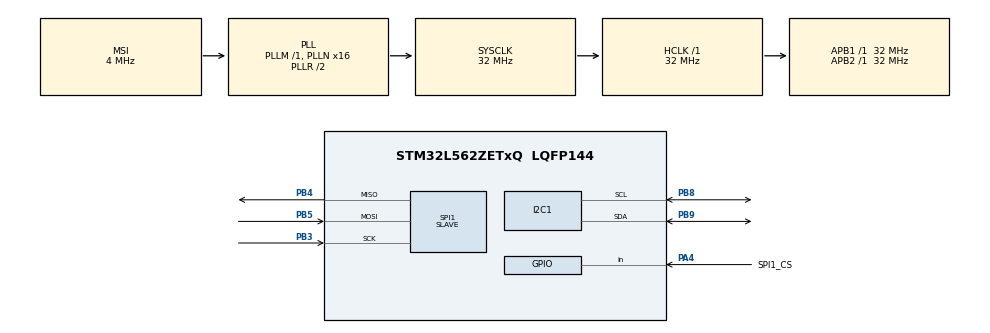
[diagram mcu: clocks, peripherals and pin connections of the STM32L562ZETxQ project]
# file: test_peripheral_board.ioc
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I2C1.OwnAddress=1
I2C1.Timing=0x00B07CB4
Mcu.Family=STM32L5
Mcu.Name=STM32L562ZETxQ
Mcu.Package=LQFP144
NVIC.PriorityGroup=NVIC_PRIORITYGROUP_3
PA4.GPIO_Label=SPI1_CS
PA4.Signal=GPIO_Input
PB3\ (JTDO/TRACESWO).Mode=Full_Duplex_Slave
PB3\ (JTDO/TRACESWO).Signal=SPI1_SCK
PB4\ (NJTRST).Mode=Full_Duplex_Slave
PB4\ (NJTRST).Signal=SPI1_MISO
PB5.Mode=Full_Duplex_Slave
PB5.Signal=SPI1_MOSI
PB8.Mode=I2C
PB8.Signal=I2C1_SCL
PB9.Mode=I2C
PB9.Signal=I2C1_SDA
ProjectManager.HeapSize=0x200
ProjectManager.StackSize=0x400
ProjectManager.TargetToolchain=STM32CubeIDE
RCC.AHBFreq_Value=32000000
RCC.APB1Freq_Value=32000000
RCC.APB1TimFreq_Value=32000000
RCC.APB2Freq_Value=32000000
RCC.APB2TimFreq_Value=32000000
RCC.CSICalibrationValue=32
RCC.CortexFreq_Value=32000000
RCC.HCLKFreq_Value=32000000
RCC.HSE_VALUE=16000000
RCC.HSI48_VALUE=48000000
RCC.HSI_VALUE=16000000
RCC.LSE_VALUE=32768
RCC.MSI_VALUE=4000000
RCC.PLL1_VCI_Range=RCC_PLL1VCIRANGE_3
RCC.PLL1_VCO_SEL=RCC_PLL1VCOMEDIUM
RCC.PLL2FRACN=0
RCC.PLL2_VCI_Range=RCC_PLL2VCIRANGE_3
RCC.PLL2_VCO_SEL=RCC_PLL2VCOWIDE
RCC.PLL3FRACN=0
RCC.PLL3_VCI_Range=RCC_PLL3VCIRANGE_3
RCC.PLL3_VCO_SEL=RCC_PLL3VCOWIDE
RCC.PLLFRACN=0
RCC.PLLN=16
RCC.ProductRev=revV
RCC.RCC_TIM_PRescaler_Selection=RCC_TIMPRES_DESACTIVATED
RCC.SYSCLKFreq_VALUE=32000000
RCC.SYSCLKSource=RCC_SYSCLKSOURCE_PLLCLK
RCC.VCOOutputFreq_Value=64000000
SPI1.DataSize=SPI_DATASIZE_8BIT
SPI1.Direction=SPI_DIRECTION_2LINES
SPI1.Mode=SPI_MODE_SLAVE
SPI1.VirtualType=VM_SLAVE
VP_PWR_VS_DBSignals.Mode=DisableDeadBatterySignals
VP_PWR_VS_SECSignals.Mode=Security/Privilege
board=custom

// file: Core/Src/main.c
/* USER CODE BEGIN Header */
/**
  ******************************************************************************
  * @file           : main.c
  * @brief          : Main program body
  ******************************************************************************
  * @attention
  *
  * Copyright (c) 2025 STMicroelectronics.
  * All rights reserved.
  *
  * This software is licensed under terms that can be found in the LICENSE file
  * in the root directory of this software component.
  * If no LICENSE file comes with this software, it is provided AS-IS.
  *
  ******************************************************************************
  */
/* USER CODE END Header */
#include "main.h"

I2C_HandleTypeDef hi2c1;

SPI_HandleTypeDef hspi1;

void SystemClock_Config(void);
static void MX_GPIO_Init(void);
static void MX_SPI1_Init(void);
static void MX_I2C1_Init(void);

int main(void)
{

  /* MCU Configuration--------------------------------------------------------*/

  /* Reset of all peripherals, Initializes the Flash interface and the Systick. */
  HAL_Init();

  /* Configure the system clock */
  SystemClock_Config();

  /* Initialize all configured peripherals */
  MX_GPIO_Init();
  MX_SPI1_Init();
  MX_I2C1_Init();

  /* Infinite loop */
  /* USER CODE BEGIN WHILE */
  while (1)
  {
	  //HAL_SPI_TransmitReceive(&hspi1, txData, rxData, 3, HAL_MAX_DELAY);
	  //HAL_I2C_Slave_Receive(&hi2c1, rxData, 3, HAL_MAX_DELAY);
	  //HAL_I2C_Slave_Receive(&hi2c1, txData, 3, HAL_MAX_DELAY);

	  HAL_Delay(1000);
    /* USER CODE END WHILE */

  }
}

void SystemClock_Config(void)
{
  RCC_OscInitTypeDef RCC_OscInitStruct = {0};
  RCC_ClkInitTypeDef RCC_ClkInitStruct = {0};

  /** Configure the main internal regulator output voltage
  */
  if (HAL_PWREx_ControlVoltageScaling(PWR_REGULATOR_VOLTAGE_SCALE1) != HAL_OK)
  {
    Error_Handler();
  }

  /** Initializes the RCC Oscillators according to the specified parameters
  * in the RCC_OscInitTypeDef structure.
  */
  RCC_OscInitStruct.OscillatorType = RCC_OSCILLATORTYPE_MSI;
  RCC_OscInitStruct.MSIState = RCC_MSI_ON;
  RCC_OscInitStruct.MSICalibrationValue = RCC_MSICALIBRATION_DEFAULT;
  RCC_OscInitStruct.MSIClockRange = RCC_MSIRANGE_6;
  RCC_OscInitStruct.PLL.PLLState = RCC_PLL_ON;
  RCC_OscInitStruct.PLL.PLLSource = RCC_PLLSOURCE_MSI;
  RCC_OscInitStruct.PLL.PLLM = 1;
  RCC_OscInitStruct.PLL.PLLN = 16;
  RCC_OscInitStruct.PLL.PLLP = RCC_PLLP_DIV7;
  RCC_OscInitStruct.PLL.PLLQ = RCC_PLLQ_DIV2;
  RCC_OscInitStruct.PLL.PLLR = RCC_PLLR_DIV2;
  if (HAL_RCC_OscConfig(&RCC_OscInitStruct) != HAL_OK)
  {
    Error_Handler();
  }

  /** Initializes the CPU, AHB and APB buses clocks
  */
  RCC_ClkInitStruct.ClockType = RCC_CLOCKTYPE_HCLK|RCC_CLOCKTYPE_SYSCLK
                              |RCC_CLOCKTYPE_PCLK1|RCC_CLOCKTYPE_PCLK2;
  RCC_ClkInitStruct.SYSCLKSource = RCC_SYSCLKSOURCE_PLLCLK;
  RCC_ClkInitStruct.AHBCLKDivider = RCC_SYSCLK_DIV1;
  RCC_ClkInitStruct.APB1CLKDivider = RCC_HCLK_DIV1;
  RCC_ClkInitStruct.APB2CLKDivider = RCC_HCLK_DIV1;

  if (HAL_RCC_ClockConfig(&RCC_ClkInitStruct, FLASH_LATENCY_1) != HAL_OK)
  {
    Error_Handler();
  }
}

static void MX_I2C1_Init(void)
{

  hi2c1.Instance = I2C1;
  hi2c1.Init.Timing = 0x00B07CB4;
  hi2c1.Init.OwnAddress1 = 2;
  hi2c1.Init.AddressingMode = I2C_ADDRESSINGMODE_7BIT;
  hi2c1.Init.DualAddressMode = I2C_DUALADDRESS_DISABLE;
  hi2c1.Init.OwnAddress2 = 0;
  hi2c1.Init.OwnAddress2Masks = I2C_OA2_NOMASK;
  hi2c1.Init.GeneralCallMode = I2C_GENERALCALL_DISABLE;
  hi2c1.Init.NoStretchMode = I2C_NOSTRETCH_DISABLE;
  if (HAL_I2C_Init(&hi2c1) != HAL_OK)
  {
    Error_Handler();
  }

  /** Configure Analogue filter
  */
  if (HAL_I2CEx_ConfigAnalogFilter(&hi2c1, I2C_ANALOGFILTER_ENABLE) != HAL_OK)
  {
    Error_Handler();
  }

  /** Configure Digital filter
  */
  if (HAL_I2CEx_ConfigDigitalFilter(&hi2c1, 0) != HAL_OK)
  {
    Error_Handler();
  }

}

static void MX_SPI1_Init(void)
{

  /* SPI1 parameter configuration*/
  hspi1.Instance = SPI1;
  hspi1.Init.Mode = SPI_MODE_SLAVE;
  hspi1.Init.Direction = SPI_DIRECTION_2LINES;
  hspi1.Init.DataSize = SPI_DATASIZE_8BIT;
  hspi1.Init.CLKPolarity = SPI_POLARITY_LOW;
  hspi1.Init.CLKPhase = SPI_PHASE_1EDGE;
  hspi1.Init.NSS = SPI_NSS_SOFT;
  hspi1.Init.FirstBit = SPI_FIRSTBIT_MSB;
  hspi1.Init.TIMode = SPI_TIMODE_DISABLE;
  hspi1.Init.CRCCalculation = SPI_CRCCALCULATION_DISABLE;
  hspi1.Init.CRCPolynomial = 7;
  hspi1.Init.CRCLength = SPI_CRC_LENGTH_DATASIZE;
  hspi1.Init.NSSPMode = SPI_NSS_PULSE_DISABLE;
  if (HAL_SPI_Init(&hspi1) != HAL_OK)
  {
    Error_Handler();
  }

}

static void MX_GPIO_Init(void)
{
  GPIO_InitTypeDef GPIO_InitStruct = {0};

  /* GPIO Ports Clock Enable */
  __HAL_RCC_GPIOA_CLK_ENABLE();
  __HAL_RCC_GPIOB_CLK_ENABLE();

  /*Configure GPIO pin : SPI1_CS_Pin */
  GPIO_InitStruct.Pin = SPI1_CS_Pin;
  GPIO_InitStruct.Mode = GPIO_MODE_INPUT;
  GPIO_InitStruct.Pull = GPIO_NOPULL;
  HAL_GPIO_Init(SPI1_CS_GPIO_Port, &GPIO_InitStruct);

}

void Error_Handler(void)
{
  __disable_irq();
  while (1)
  {
  }
}
